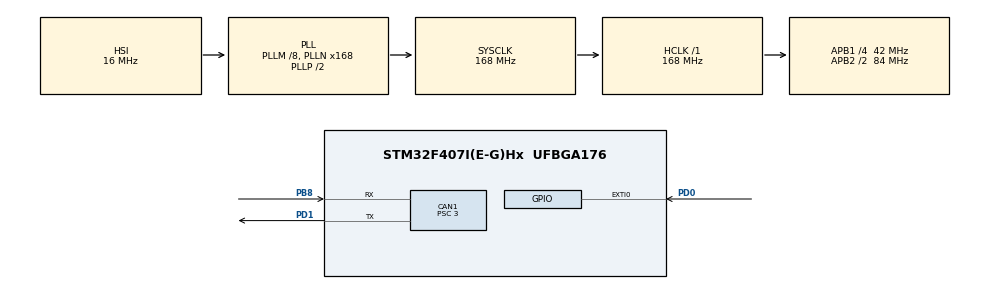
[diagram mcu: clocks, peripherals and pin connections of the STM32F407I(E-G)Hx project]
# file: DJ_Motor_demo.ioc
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CAN1.BS1=CAN_BS1_9TQ
CAN1.BS2=CAN_BS2_4TQ
CAN1.CalculateBaudRate=1000000
CAN1.CalculateTimeBit=1000
CAN1.CalculateTimeQuantum=71.42857142857143
CAN1.Prescaler=3
Mcu.Family=STM32F4
Mcu.Name=STM32F407I(E-G)Hx
Mcu.Package=UFBGA176
NVIC.CAN1_RX0_IRQn=true\:0\:0\:false\:false\:true\:true\:true\:true
NVIC.CAN1_RX1_IRQn=true\:0\:0\:false\:false\:true\:true\:true\:true
NVIC.PriorityGroup=NVIC_PRIORITYGROUP_4
PA13.Mode=Serial_Wire
PA13.Signal=SYS_JTMS-SWDIO
PA14.Mode=Serial_Wire
PA14.Signal=SYS_JTCK-SWCLK
PB8.Mode=CAN_Activate
PB8.Signal=CAN1_RX
PD0.Signal=GPXTI0
PD1.Mode=CAN_Activate
PD1.Signal=CAN1_TX
PH0-OSC_IN.Mode=HSE-External-Oscillator
PH0-OSC_IN.Signal=RCC_OSC_IN
PH1-OSC_OUT.Mode=HSE-External-Oscillator
PH1-OSC_OUT.Signal=RCC_OSC_OUT
ProjectManager.HeapSize=0x200
ProjectManager.StackSize=0x400
ProjectManager.TargetToolchain=MDK-ARM V5.32
RCC.48MHZClocksFreq_Value=84000000
RCC.AHBFreq_Value=168000000
RCC.APB1CLKDivider=RCC_HCLK_DIV4
RCC.APB1Freq_Value=42000000
RCC.APB1TimFreq_Value=84000000
RCC.APB2CLKDivider=RCC_HCLK_DIV2
RCC.APB2Freq_Value=84000000
RCC.APB2TimFreq_Value=168000000
RCC.CortexFreq_Value=168000000
RCC.HCLKFreq_Value=168000000
RCC.HSE_VALUE=25000000
RCC.HSI_VALUE=16000000
RCC.LSE_VALUE=32768
RCC.PLLM=8
RCC.PLLN=168
RCC.SYSCLKFreq_VALUE=168000000
RCC.SYSCLKSource=RCC_SYSCLKSOURCE_PLLCLK
RCC.VCOOutputFreq_Value=336000000
board=custom

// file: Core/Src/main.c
/* USER CODE BEGIN Header */
/**
  ******************************************************************************
  * @file           : main.c
  * @brief          : Main program body
  ******************************************************************************
  * @attention
  *
  * Copyright (c) 2024 STMicroelectronics.
  * All rights reserved.
  *
  * This software is licensed under terms that can be found in the LICENSE file
  * in the root directory of this software component.
  * If no LICENSE file comes with this software, it is provided AS-IS.
  *
  ******************************************************************************
  */
/* USER CODE END Header */
#include "main.h"
#include "can.h"
#include "gpio.h"

/* USER CODE BEGIN Includes */
#include "DJ_Motor.h"
/* USER CODE END Includes */

/* USER CODE BEGIN PTD */
typedef struct
{
  float kp;
  float ki;
  float kd;
  /* data */
}Pid;
/* USER CODE END PTD */

/* USER CODE BEGIN PV */
float t_v,t_j;
/* USER CODE END PV */

void SystemClock_Config(void);
/* USER CODE BEGIN PFP */

//速度pid
float pid_v(float target,float current)
{

  Pid pid_v;
  pid_v.kp = 15;
  pid_v.ki = 0.7;
  pid_v.kd = 3;

  float c_err,l_err,i_err;
//  c_err = (yaokong.ch3-1024)/660*300 - motor_chassis.speed_rpm;
	c_err = target -current ;
  float out_v = pid_v.kp * c_err + pid_v.kd *(c_err-l_err) + pid_v.ki *i_err;
  l_err = c_err;
  i_err += c_err;
	if(i_err >10000) i_err = 10000; //积分限幅
	if(i_err <-10000) i_err = 10000;

	return out_v;
};

//角度pid
float pid_j(float target,float current)
{

  Pid pid_j;
  pid_j.kp = 9;
  pid_j.ki = 0.7;
  pid_j.kd = 9;

  float c_err,l_err,i_err;
//  c_err = (yaokong.ch3-1024)/660*300 - motor_chassis.speed_rpm;
	c_err = target -current ;
	//角度过零处理
		if(c_err >4000)
		{
		c_err = (c_err - 8191);
	}
	else if(c_err < -4000)
	{
		c_err = (c_err + 8191);
	}
	else c_err = c_err;
  float out_j = pid_j.kp * c_err + pid_j.kd *(c_err-l_err) + pid_j.ki *i_err;
  l_err = c_err;
  i_err += c_err;

	if(i_err >1000) i_err = 1000;
	if(i_err <-1000) i_err = -1000;

	return out_j;
};
/* USER CODE END PFP */

int main(void)
{

  /* MCU Configuration--------------------------------------------------------*/

  /* Reset of all peripherals, Initializes the Flash interface and the Systick. */
  HAL_Init();

  /* Configure the system clock */
  SystemClock_Config();

  /* Initialize all configured peripherals */
  MX_GPIO_Init();
  MX_CAN1_Init();
  /* USER CODE BEGIN 2 */
	//仅初始化函数就可接收信息
	//记得查看电调ID
	DJ_Motor_Init(&hcan1);
  /* USER CODE END 2 */

  /* Infinite loop */
  /* USER CODE BEGIN WHILE */
  while (1)
  {
		pid_j(t_j,motor_chassis_3508_1.ecd);
		pid_v(t_v,motor_chassis_3508_2.speed_rpm);
		CAN_Motor_Control_3508(pid_j(t_j,motor_chassis_3508_1.ecd),pid_v(t_v,motor_chassis_3508_2.speed_rpm),0,0);
    /* USER CODE END WHILE */

  }
}

void SystemClock_Config(void)
{
  RCC_OscInitTypeDef RCC_OscInitStruct = {0};
  RCC_ClkInitTypeDef RCC_ClkInitStruct = {0};

  /** Configure the main internal regulator output voltage
  */
  __HAL_RCC_PWR_CLK_ENABLE();
  __HAL_PWR_VOLTAGESCALING_CONFIG(PWR_REGULATOR_VOLTAGE_SCALE1);

  /** Initializes the RCC Oscillators according to the specified parameters
  * in the RCC_OscInitTypeDef structure.
  */
  RCC_OscInitStruct.OscillatorType = RCC_OSCILLATORTYPE_HSI;
  RCC_OscInitStruct.HSIState = RCC_HSI_ON;
  RCC_OscInitStruct.HSICalibrationValue = RCC_HSICALIBRATION_DEFAULT;
  RCC_OscInitStruct.PLL.PLLState = RCC_PLL_ON;
  RCC_OscInitStruct.PLL.PLLSource = RCC_PLLSOURCE_HSI;
  RCC_OscInitStruct.PLL.PLLM = 8;
  RCC_OscInitStruct.PLL.PLLN = 168;
  RCC_OscInitStruct.PLL.PLLP = RCC_PLLP_DIV2;
  RCC_OscInitStruct.PLL.PLLQ = 4;
  if (HAL_RCC_OscConfig(&RCC_OscInitStruct) != HAL_OK)
  {
    Error_Handler();
  }

  /** Initializes the CPU, AHB and APB buses clocks
  */
  RCC_ClkInitStruct.ClockType = RCC_CLOCKTYPE_HCLK|RCC_CLOCKTYPE_SYSCLK
                              |RCC_CLOCKTYPE_PCLK1|RCC_CLOCKTYPE_PCLK2;
  RCC_ClkInitStruct.SYSCLKSource = RCC_SYSCLKSOURCE_PLLCLK;
  RCC_ClkInitStruct.AHBCLKDivider = RCC_SYSCLK_DIV1;
  RCC_ClkInitStruct.APB1CLKDivider = RCC_HCLK_DIV4;
  RCC_ClkInitStruct.APB2CLKDivider = RCC_HCLK_DIV2;

  if (HAL_RCC_ClockConfig(&RCC_ClkInitStruct, FLASH_LATENCY_5) != HAL_OK)
  {
    Error_Handler();
  }
}

void Error_Handler(void)
{
  __disable_irq();
  while (1)
  {
  }
}
